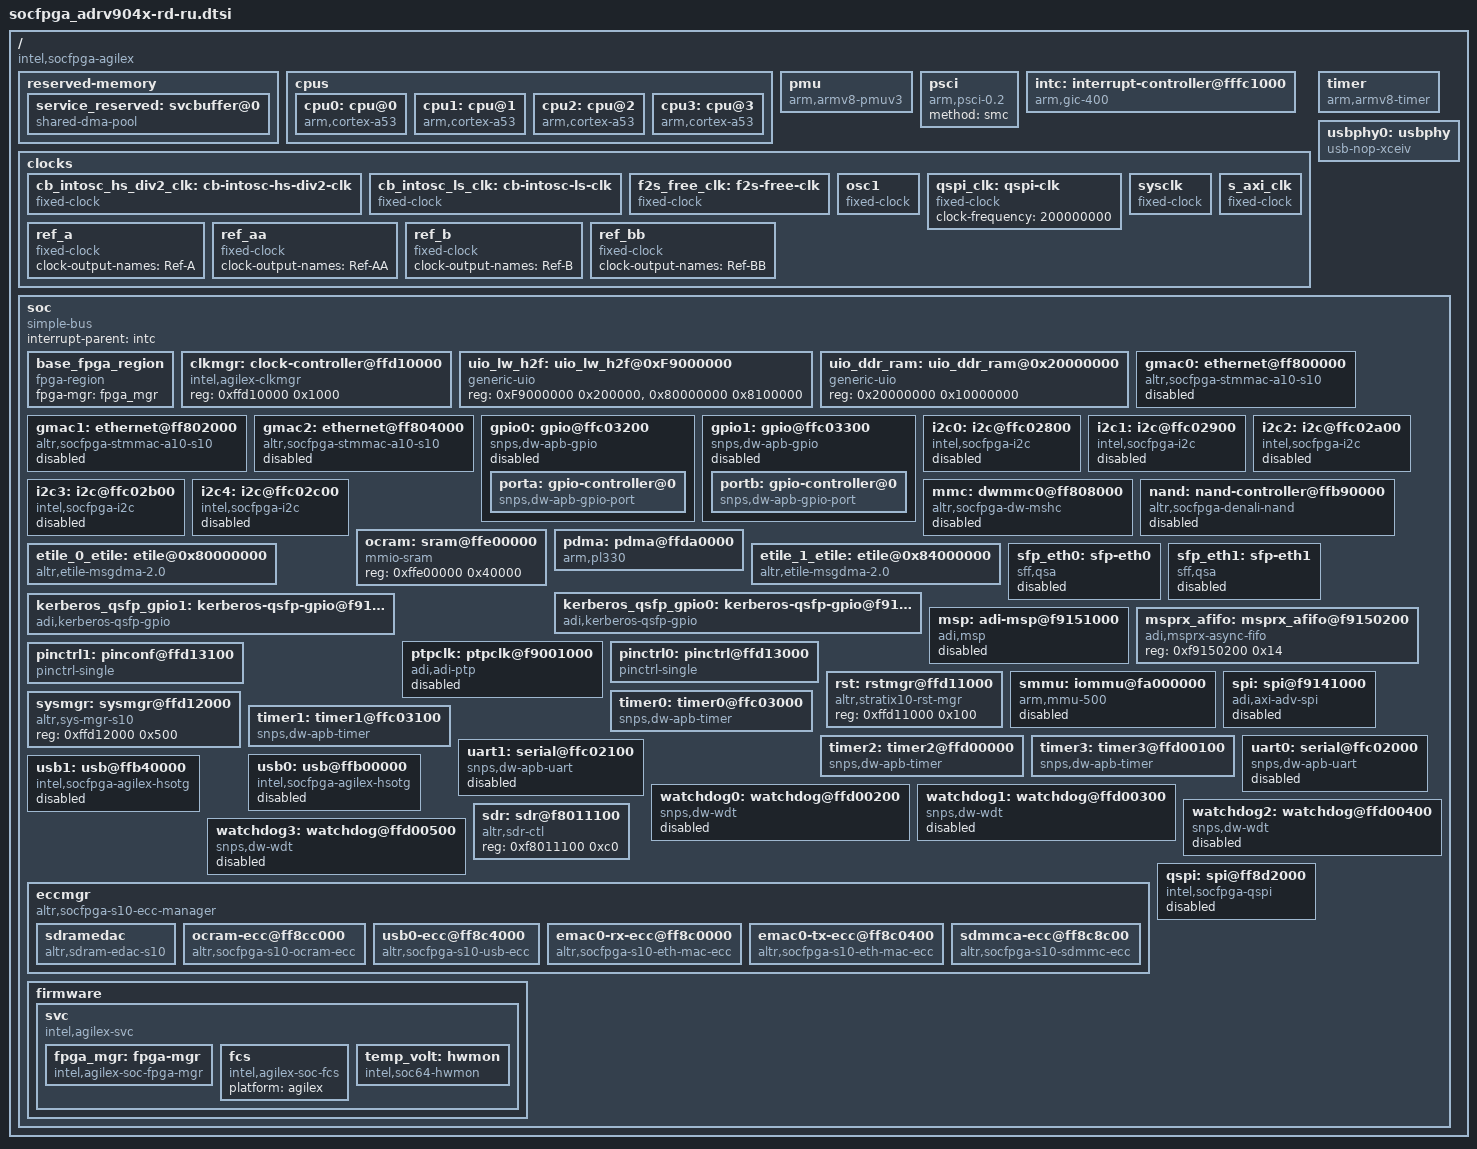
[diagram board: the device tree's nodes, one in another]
// SPDX-License-Identifier:     GPL-2.0
/*
 * Copyright (C) 2019, Intel Corporation
 */

/dts-v1/;
#include <dt-bindings/reset/altr,rst-mgr-s10.h>
#include <dt-bindings/gpio/gpio.h>
#include <dt-bindings/interrupt-controller/arm-gic.h>
#include <dt-bindings/clock/agilex-clock.h>
#include <dt-bindings/clock/ad9545.h>

/ {
	compatible = "intel,socfpga-agilex";
	#address-cells = <2>;
	#size-cells = <2>;

	reserved-memory {
		#address-cells = <2>;
		#size-cells = <2>;
		ranges;

		service_reserved: svcbuffer@0 {
			compatible = "shared-dma-pool";
			reg = <0x0 0x0 0x0 0x2000000>;
			alignment = <0x1000>;
			no-map;
		};
	};

	cpus {
		#address-cells = <1>;
		#size-cells = <0>;

		cpu0: cpu@0 {
			compatible = "arm,cortex-a53";
			device_type = "cpu";
			enable-method = "psci";
			reg = <0x0>;
		};

		cpu1: cpu@1 {
			compatible = "arm,cortex-a53";
			device_type = "cpu";
			enable-method = "psci";
			reg = <0x1>;
		};

		cpu2: cpu@2 {
			compatible = "arm,cortex-a53";
			device_type = "cpu";
			enable-method = "psci";
			reg = <0x2>;
		};

		cpu3: cpu@3 {
			compatible = "arm,cortex-a53";
			device_type = "cpu";
			enable-method = "psci";
			reg = <0x3>;
		};
	};

	pmu {
		compatible = "arm,armv8-pmuv3";
		interrupts = <GIC_SPI 170 IRQ_TYPE_LEVEL_HIGH>,
			     <GIC_SPI 171 IRQ_TYPE_LEVEL_HIGH>,
			     <GIC_SPI 172 IRQ_TYPE_LEVEL_HIGH>,
			     <GIC_SPI 173 IRQ_TYPE_LEVEL_HIGH>;
		interrupt-affinity = <&cpu0>,
				     <&cpu1>,
				     <&cpu2>,
				     <&cpu3>;
		interrupt-parent = <&intc>;
	};

	psci {
		compatible = "arm,psci-0.2";
		method = "smc";
	};

	intc: interrupt-controller@fffc1000 {
		compatible = "arm,gic-400", "arm,cortex-a15-gic";
		#interrupt-cells = <3>;
		interrupt-controller;
		reg = <0x0 0xfffc1000 0x0 0x1000>,
		      <0x0 0xfffc2000 0x0 0x2000>,
		      <0x0 0xfffc4000 0x0 0x2000>,
		      <0x0 0xfffc6000 0x0 0x2000>;
	};

	clocks {
		cb_intosc_hs_div2_clk: cb-intosc-hs-div2-clk {
			#clock-cells = <0>;
			compatible = "fixed-clock";
		};

		cb_intosc_ls_clk: cb-intosc-ls-clk {
			#clock-cells = <0>;
			compatible = "fixed-clock";
		};

		f2s_free_clk: f2s-free-clk {
			#clock-cells = <0>;
			compatible = "fixed-clock";
		};

		osc1: osc1 {
			#clock-cells = <0>;
			compatible = "fixed-clock";
		};

		qspi_clk: qspi-clk {
			#clock-cells = <0>;
			compatible = "fixed-clock";
			clock-frequency = <200000000>;
		};

		sysclk: sysclk {
			#clock-cells = <0>;
			compatible = "fixed-clock";
		};

		s_axi_clk: s_axi_clk {
			#clock-cells = <0>;
			compatible = "fixed-clock";
		};

		/* for AD9545 reference clocks */
		ref_a: ref_a {
			#clock-cells = <0>;
			compatible = "fixed-clock";
			clock-output-names = "Ref-A";
		};

		ref_aa: ref_aa {
			#clock-cells = <0>;
			compatible = "fixed-clock";
			clock-output-names = "Ref-AA";
		};

		ref_b: ref_b {
			#clock-cells = <0>;
			compatible = "fixed-clock";
			clock-output-names = "Ref-B";
		};

		ref_bb: ref_bb {
			#clock-cells = <0>;
			compatible = "fixed-clock";
			clock-output-names = "Ref-BB";
		};
	};

	timer {
		compatible = "arm,armv8-timer";
		interrupt-parent = <&intc>;
		interrupts = <GIC_PPI 13 (GIC_CPU_MASK_SIMPLE(4) | IRQ_TYPE_LEVEL_LOW)>,
			     <GIC_PPI 14 (GIC_CPU_MASK_SIMPLE(4) | IRQ_TYPE_LEVEL_LOW)>,
			     <GIC_PPI 11 (GIC_CPU_MASK_SIMPLE(4) | IRQ_TYPE_LEVEL_LOW)>,
			     <GIC_PPI 10 (GIC_CPU_MASK_SIMPLE(4) | IRQ_TYPE_LEVEL_LOW)>;
	};

	usbphy0: usbphy {
		#phy-cells = <0>;
		compatible = "usb-nop-xceiv";
		status = "okay";
	};

	soc {
		#address-cells = <1>;
		#size-cells = <1>;
		compatible = "simple-bus";
		device_type = "soc";
		interrupt-parent = <&intc>;
		ranges = <0 0 0 0xffffffff>;

		base_fpga_region {
			#address-cells = <0x2>;
			#size-cells = <0x2>;
			compatible = "fpga-region";
			fpga-mgr = <&fpga_mgr>;
		};

		clkmgr: clock-controller@ffd10000 {
			compatible = "intel,agilex-clkmgr";
			reg = <0xffd10000 0x1000>;
			#clock-cells = <1>;
		};

		uio_lw_h2f: uio_lw_h2f@0xF9000000 {
				compatible = "generic-uio";
				reg = <0xF9000000 0x200000>,
				      <0x80000000 0x8100000>;
				/*interrupts = <0 29 4>;*/
		};

		uio_ddr_ram: uio_ddr_ram@0x20000000 {
				compatible = "generic-uio";
				reg = <0x20000000 0x10000000>;
				/*interrupts = <0 29 4>;*/
		};

		gmac0: ethernet@ff800000 {
			compatible = "altr,socfpga-stmmac-a10-s10", "snps,dwmac-3.74a", "snps,dwmac";
			reg = <0xff800000 0x2000>;
			interrupts = <GIC_SPI 90 IRQ_TYPE_LEVEL_HIGH>;
			interrupt-names = "macirq";
			mac-address = [00 00 00 00 00 00];
			resets = <&rst EMAC0_RESET>, <&rst EMAC0_OCP_RESET>;
			reset-names = "stmmaceth", "stmmaceth-ocp";
			tx-fifo-depth = <16384>;
			rx-fifo-depth = <16384>;
			snps,multicast-filter-bins = <256>;
			iommus = <&smmu 1>;
			altr,sysmgr-syscon = <&sysmgr 0x44 0>;
			clocks = <&clkmgr AGILEX_EMAC0_CLK>, <&clkmgr AGILEX_EMAC_PTP_CLK>;
			clock-names = "stmmaceth", "ptp_ref";
			status = "disabled";
		};

		gmac1: ethernet@ff802000 {
			compatible = "altr,socfpga-stmmac-a10-s10", "snps,dwmac-3.74a", "snps,dwmac";
			reg = <0xff802000 0x2000>;
			interrupts = <GIC_SPI 91 IRQ_TYPE_LEVEL_HIGH>;
			interrupt-names = "macirq";
			mac-address = [00 00 00 00 00 00];
			resets = <&rst EMAC1_RESET>, <&rst EMAC1_OCP_RESET>;
			reset-names = "stmmaceth", "stmmaceth-ocp";
			tx-fifo-depth = <16384>;
			rx-fifo-depth = <16384>;
			snps,multicast-filter-bins = <256>;
			iommus = <&smmu 2>;
			altr,sysmgr-syscon = <&sysmgr 0x48 0>;
			clocks = <&clkmgr AGILEX_EMAC1_CLK>, <&clkmgr AGILEX_EMAC_PTP_CLK>;
			clock-names = "stmmaceth", "ptp_ref";
			status = "disabled";
		};

		gmac2: ethernet@ff804000 {
			compatible = "altr,socfpga-stmmac-a10-s10", "snps,dwmac-3.74a", "snps,dwmac";
			reg = <0xff804000 0x2000>;
			interrupts = <GIC_SPI 92 IRQ_TYPE_LEVEL_HIGH>;
			interrupt-names = "macirq";
			mac-address = [00 00 00 00 00 00];
			resets = <&rst EMAC2_RESET>, <&rst EMAC2_OCP_RESET>;
			reset-names = "stmmaceth", "stmmaceth-ocp";
			tx-fifo-depth = <16384>;
			rx-fifo-depth = <16384>;
			snps,multicast-filter-bins = <256>;
			iommus = <&smmu 3>;
			altr,sysmgr-syscon = <&sysmgr 0x4c 0>;
			clocks = <&clkmgr AGILEX_EMAC2_CLK>, <&clkmgr AGILEX_EMAC_PTP_CLK>;
			clock-names = "stmmaceth", "ptp_ref";
			status = "disabled";
		};

		gpio0: gpio@ffc03200 {
			#address-cells = <1>;
			#size-cells = <0>;
			compatible = "snps,dw-apb-gpio";
			reg = <0xffc03200 0x100>;
			resets = <&rst GPIO0_RESET>;
			status = "disabled";

			porta: gpio-controller@0 {
				compatible = "snps,dw-apb-gpio-port";
				gpio-controller;
				#gpio-cells = <2>;
				snps,nr-gpios = <24>;
				reg = <0>;
				interrupt-controller;
				#interrupt-cells = <2>;
				interrupts = <GIC_SPI 110 IRQ_TYPE_LEVEL_HIGH>;
			};
		};

		gpio1: gpio@ffc03300 {
			#address-cells = <1>;
			#size-cells = <0>;
			compatible = "snps,dw-apb-gpio";
			reg = <0xffc03300 0x100>;
			resets = <&rst GPIO1_RESET>;
			status = "disabled";

			portb: gpio-controller@0 {
				compatible = "snps,dw-apb-gpio-port";
				gpio-controller;
				#gpio-cells = <2>;
				snps,nr-gpios = <24>;
				reg = <0>;
				interrupt-controller;
				#interrupt-cells = <2>;
				interrupts = <GIC_SPI 111 IRQ_TYPE_LEVEL_HIGH>;
			};
		};

		i2c0: i2c@ffc02800 {
			#address-cells = <1>;
			#size-cells = <0>;
			compatible = "intel,socfpga-i2c", "snps,designware-i2c";
			reg = <0xffc02800 0x100>;
			interrupts = <GIC_SPI 103 IRQ_TYPE_LEVEL_HIGH>;
			resets = <&rst I2C0_RESET>;
			clocks = <&clkmgr AGILEX_L4_SP_CLK>;
			status = "disabled";
		};

		i2c1: i2c@ffc02900 {
			#address-cells = <1>;
			#size-cells = <0>;
			compatible = "intel,socfpga-i2c", "snps,designware-i2c";
			reg = <0xffc02900 0x100>;
			interrupts = <GIC_SPI 104 IRQ_TYPE_LEVEL_HIGH>;
			resets = <&rst I2C1_RESET>;
			clocks = <&clkmgr AGILEX_L4_SP_CLK>;
			status = "disabled";
		};

		i2c2: i2c@ffc02a00 {
			#address-cells = <1>;
			#size-cells = <0>;
			compatible = "intel,socfpga-i2c", "snps,designware-i2c";
			reg = <0xffc02a00 0x100>;
			interrupts = <GIC_SPI 105 IRQ_TYPE_LEVEL_HIGH>;
			resets = <&rst I2C2_RESET>;
			clocks = <&clkmgr AGILEX_L4_SP_CLK>;
			status = "disabled";
		};

		i2c3: i2c@ffc02b00 {
			#address-cells = <1>;
			#size-cells = <0>;
			compatible = "intel,socfpga-i2c", "snps,designware-i2c";
			reg = <0xffc02b00 0x100>;
			interrupts = <GIC_SPI 106 IRQ_TYPE_LEVEL_HIGH>;
			resets = <&rst I2C3_RESET>;
			clocks = <&clkmgr AGILEX_L4_SP_CLK>;
			status = "disabled";
		};

		i2c4: i2c@ffc02c00 {
			#address-cells = <1>;
			#size-cells = <0>;
			compatible = "intel,socfpga-i2c", "snps,designware-i2c";
			reg = <0xffc02c00 0x100>;
			interrupts = <GIC_SPI 107 IRQ_TYPE_LEVEL_HIGH>;
			resets = <&rst I2C4_RESET>;
			clocks = <&clkmgr AGILEX_L4_SP_CLK>;
			status = "disabled";
		};

		mmc: dwmmc0@ff808000 {
			#address-cells = <1>;
			#size-cells = <0>;
			compatible = "altr,socfpga-dw-mshc";
			reg = <0xff808000 0x1000>;
			interrupts = <GIC_SPI 96 IRQ_TYPE_LEVEL_HIGH>;
			fifo-depth = <0x400>;
			resets = <&rst SDMMC_RESET>;
			reset-names = "reset";
			clocks = <&clkmgr AGILEX_L4_MP_CLK>,
				 <&clkmgr AGILEX_SDMMC_CLK>;
			clock-names = "biu", "ciu";
			iommus = <&smmu 5>;
			status = "disabled";
		};

		nand: nand-controller@ffb90000 {
			#address-cells = <1>;
			#size-cells = <0>;
			compatible = "altr,socfpga-denali-nand";
			reg = <0xffb90000 0x10000>,
			      <0xffb80000 0x1000>;
			reg-names = "nand_data", "denali_reg";
			interrupts = <GIC_SPI 97 IRQ_TYPE_LEVEL_HIGH>;
			clocks = <&clkmgr AGILEX_NAND_CLK>,
				 <&clkmgr AGILEX_NAND_X_CLK>,
				 <&clkmgr AGILEX_NAND_ECC_CLK>;
			clock-names = "nand", "nand_x", "ecc";
			resets = <&rst NAND_RESET>, <&rst NAND_OCP_RESET>;
			status = "disabled";
		};

		ocram: sram@ffe00000 {
			compatible = "mmio-sram";
			reg = <0xffe00000 0x40000>;
		};

		pdma: pdma@ffda0000 {
			compatible = "arm,pl330", "arm,primecell";
			reg = <0xffda0000 0x1000>;
			interrupts = <GIC_SPI 81 IRQ_TYPE_LEVEL_HIGH>,
				     <GIC_SPI 82 IRQ_TYPE_LEVEL_HIGH>,
				     <GIC_SPI 83 IRQ_TYPE_LEVEL_HIGH>,
				     <GIC_SPI 84 IRQ_TYPE_LEVEL_HIGH>,
				     <GIC_SPI 85 IRQ_TYPE_LEVEL_HIGH>,
				     <GIC_SPI 86 IRQ_TYPE_LEVEL_HIGH>,
				     <GIC_SPI 87 IRQ_TYPE_LEVEL_HIGH>,
				     <GIC_SPI 88 IRQ_TYPE_LEVEL_HIGH>,
				     <GIC_SPI 89 IRQ_TYPE_LEVEL_HIGH>;
			#dma-cells = <1>;
			#dma-channels = <8>;
			#dma-requests = <32>;
			resets = <&rst DMA_RESET>, <&rst DMA_OCP_RESET>;
			reset-names = "dma", "dma-ocp";
			clocks = <&clkmgr AGILEX_L4_MAIN_CLK>;
			clock-names = "apb_pclk";
		};

		etile_0_etile: etile@0x80000000{
			compatible = "altr,etile-msgdma-2.0";
			reg-names = "eth_reconfig", "eth_ctrl";
			reg = <0x80000000 0x04000000>,
			      <0xf91401f0 0x4>;
			//dma-coherent;
			phy-mode = "25gbase-r";
			sfp = <&sfp_eth0>;

			/*
			clocks = <&ptp_ctrl_10G_clk>;
			clock-names = "tod_clk";
			interrupt-parent = <&intc>;
			interrupt-names = "tx_irq", "rx_irq";
			interrupts = <0 24 4>,
					<0 25 4>;
			rx-fifo-depth = <0x4000>;
			tx-fifo-depth = <0x1000>;
			rx-fifo-almost-full = <0x2000>;
			rx-fifo-almost-empty = <0x1000>;
			*/
			local-mac-address = [00 11 22 33 44 50];
			altr,tx-pma-delay-ns = <0xD>;
			altr,rx-pma-delay-ns = <0x8>;
			altr,tx-pma-delay-fns = <0x24D>;
			altr,rx-pma-delay-fns = <0x3E97>;
			altr,tx-external-phy-delay-ns = <0x0>;
			altr,rx-external-phy-delay-ns = <0x0>;
			fec-type = "kr-fec";
			fec-cw-pos-rx = <3>;
			//altr,has-ptp;
			status = "okay";
		};

		etile_1_etile: etile@0x84000000{
			compatible = "altr,etile-msgdma-2.0";
			reg-names = "eth_reconfig", "eth_ctrl";
			reg = <0x84000000 0x04000000>,
			      <0xf91401f4 0x4>;
			//dma-coherent;
			phy-mode = "25gbase-r";
			sfp = <&sfp_eth1>;

			/*
			clocks = <&ptp_ctrl_10G_clk>;
			clock-names = "tod_clk";
			interrupt-parent = <&intc>;
			interrupt-names = "tx_irq", "rx_irq";
			interrupts = <0 24 4>,
					<0 25 4>;
			rx-fifo-depth = <0x4000>;
			tx-fifo-depth = <0x1000>;
			rx-fifo-almost-full = <0x2000>;
			rx-fifo-almost-empty = <0x1000>;
			*/
			local-mac-address = [00 11 22 33 44 51];
			altr,tx-pma-delay-ns = <0xD>;
			altr,rx-pma-delay-ns = <0x8>;
			altr,tx-pma-delay-fns = <0x24D>;
			altr,rx-pma-delay-fns = <0x3E97>;
			altr,tx-external-phy-delay-ns = <0x0>;
			altr,rx-external-phy-delay-ns = <0x0>;
			fec-type = "kr-fec";
			fec-cw-pos-rx = <3>;
			altr,has-ptp;
			status = "okay";
		};

		sfp_eth0: sfp-eth0 {
			compatible = "sff,qsa";
			mod-def0-gpios = <&kerberos_qsfp_gpio0 4 GPIO_ACTIVE_LOW>;
			qsfpdd_modseln-gpio = <&kerberos_qsfp_gpio0 1 GPIO_ACTIVE_LOW>;
			maximum-power-milliwatt = <1000>;
			status = "disabled";
		};

		sfp_eth1: sfp-eth1 {
			compatible = "sff,qsa";
			mod-def0-gpios = <&kerberos_qsfp_gpio1 4 GPIO_ACTIVE_LOW>;
			qsfpdd_modseln-gpio = <&kerberos_qsfp_gpio1 1 GPIO_ACTIVE_LOW>;
			maximum-power-milliwatt = <1000>;
			status = "disabled";
		};

		kerberos_qsfp_gpio0: kerberos-qsfp-gpio@f9140154{
			compatible = "adi,kerberos-qsfp-gpio";
			reg = <0xf9140154 0x14>;
			#gpio-cells = <2>;
			gpio-controller;
			status = "okay";
		};

		kerberos_qsfp_gpio1: kerberos-qsfp-gpio@f9140168{
			compatible = "adi,kerberos-qsfp-gpio";
			reg = <0xf9140168 0x14>;
			#gpio-cells = <2>;
			gpio-controller;
			status = "okay";
		};

		msp: adi-msp@f9151000 {
			#address-cells = <1>;
			#size-cells = <1>;
			compatible = "adi,msp";
			reg = <0x8800b800 0x2800>, <0x88004300 0x1300>,
			      <0xf9150200 0x14>,
			      <0xf91401d0 0x10>,
			      <0xf9150000 0x50>, <0xf9151000 0x118>,
			      <0xf9150100 0x4>,
			      <0xf9152000 0x118>, <0xf9150300 0x50>,
			      <0xf9150500 0x50>;
			reg-names = "oif_tx", "oif_rx",
				    "async_fifo_rx",
				    "axi_palau_gpio_msp_ctrl",
				    "rx_dma", "rx",
				    "dde_tester",
				    "tx", "tx_dma",
				    "status_dma";
			/* 53 + 32 = 85 --> interrupt_2_sic */
			/* 55 + 32 = 87 --> dde_error_intr */
			interrupts = <0 53 4>, <0 55 4>,
				     <0 60 4>, <0 58 4>,
				     <0 63 4>, <0 64 4>;
			interrupt-names = "rx_dmadone_irq", "rx_dde_error_irq",
					  "tx_dmadone_irq", "tx_dde_error_irq",
					  "status_dmadone_irq",
					  "status_dde_error_irq";
			local-mac-address = [00 11 22 33 44 52];
			adi,etile = <&etile_1_etile>;
			status = "disabled";
		};

		msprx_afifo: msprx_afifo@f9150200 {
			#address-cells = <1>;
			#size-cells = <1>;
			compatible = "adi,msprx-async-fifo";
			reg = <0xf9150200 0x14>;
			reg-names = "msprx_afifo";
		};

		ptpclk: ptpclk@f9001000 {
			compatible = "adi,adi-ptp";
			reg = <0xf9001000 0xff>, <0xf9140144 0x4>;
			reg-names = "tod", "axi_palau_gpio_pps_ctrl";
			adi,max-adj = <131072>;
			adi,trigger-mode = <1>;
			adi,trigger-delay-tick = <491520>;
			adi,ppsx-delay-offset-ns = <0>;
			adi,ppsx-pulse-width-ns = <256>;
			status = "disabled";
		};

		pinctrl0: pinctrl@ffd13000 {
			compatible = "pinctrl-single";
			#pinctrl-cells = <1>;
			reg = <0xffd13000 0xa0>;
			pinctrl-single,register-width = <32>;
			pinctrl-single,function-mask = <0x0000000f>;
		};

		pinctrl1: pinconf@ffd13100 {
			compatible = "pinctrl-single";
			#pinctrl-cells = <1>;
			reg = <0xffd13100 0x20>;
			pinctrl-single,register-width = <32>;
		};

		rst: rstmgr@ffd11000 {
			#reset-cells = <1>;
			compatible = "altr,stratix10-rst-mgr";
			reg = <0xffd11000 0x100>;
		};

		smmu: iommu@fa000000 {
			compatible = "arm,mmu-500", "arm,smmu-v2";
			reg = <0xfa000000 0x40000>;
			#global-interrupts = <2>;
			#iommu-cells = <1>;
			interrupt-parent = <&intc>;
			/* Global Secure Fault */
			interrupts = <GIC_SPI 128 IRQ_TYPE_LEVEL_HIGH>,
				/* Global Non-secure Fault */
				<GIC_SPI 129 IRQ_TYPE_LEVEL_HIGH>,
				/* Non-secure Context Interrupts (32) */
				<GIC_SPI 138 IRQ_TYPE_LEVEL_HIGH>,
				<GIC_SPI 139 IRQ_TYPE_LEVEL_HIGH>,
				<GIC_SPI 140 IRQ_TYPE_LEVEL_HIGH>,
				<GIC_SPI 141 IRQ_TYPE_LEVEL_HIGH>,
				<GIC_SPI 142 IRQ_TYPE_LEVEL_HIGH>,
				<GIC_SPI 143 IRQ_TYPE_LEVEL_HIGH>,
				<GIC_SPI 144 IRQ_TYPE_LEVEL_HIGH>,
				<GIC_SPI 145 IRQ_TYPE_LEVEL_HIGH>,
				<GIC_SPI 146 IRQ_TYPE_LEVEL_HIGH>,
				<GIC_SPI 147 IRQ_TYPE_LEVEL_HIGH>,
				<GIC_SPI 148 IRQ_TYPE_LEVEL_HIGH>,
				<GIC_SPI 149 IRQ_TYPE_LEVEL_HIGH>,
				<GIC_SPI 150 IRQ_TYPE_LEVEL_HIGH>,
				<GIC_SPI 151 IRQ_TYPE_LEVEL_HIGH>,
				<GIC_SPI 152 IRQ_TYPE_LEVEL_HIGH>,
				<GIC_SPI 153 IRQ_TYPE_LEVEL_HIGH>,
				<GIC_SPI 154 IRQ_TYPE_LEVEL_HIGH>,
				<GIC_SPI 155 IRQ_TYPE_LEVEL_HIGH>,
				<GIC_SPI 156 IRQ_TYPE_LEVEL_HIGH>,
				<GIC_SPI 157 IRQ_TYPE_LEVEL_HIGH>,
				<GIC_SPI 158 IRQ_TYPE_LEVEL_HIGH>,
				<GIC_SPI 159 IRQ_TYPE_LEVEL_HIGH>,
				<GIC_SPI 160 IRQ_TYPE_LEVEL_HIGH>,
				<GIC_SPI 161 IRQ_TYPE_LEVEL_HIGH>,
				<GIC_SPI 162 IRQ_TYPE_LEVEL_HIGH>,
				<GIC_SPI 163 IRQ_TYPE_LEVEL_HIGH>,
				<GIC_SPI 164 IRQ_TYPE_LEVEL_HIGH>,
				<GIC_SPI 165 IRQ_TYPE_LEVEL_HIGH>,
				<GIC_SPI 166 IRQ_TYPE_LEVEL_HIGH>,
				<GIC_SPI 167 IRQ_TYPE_LEVEL_HIGH>,
				<GIC_SPI 168 IRQ_TYPE_LEVEL_HIGH>,
				<GIC_SPI 169 IRQ_TYPE_LEVEL_HIGH>;
			stream-match-mask = <0x7ff0>;
			clocks = <&clkmgr AGILEX_MPU_CCU_CLK>,
				 <&clkmgr AGILEX_L3_MAIN_FREE_CLK>,
				 <&clkmgr AGILEX_L4_MAIN_CLK>;
			status = "disabled";
		};

		spi: spi@f9141000{
			compatible = "adi,axi-adv-spi";
			reg = <0xf9141000 0x1000>;
			#address-cells = <1>;
			#size-cells = <0>;
			clocks = <&s_axi_clk>;
			status = "disabled";
		};

		sysmgr: sysmgr@ffd12000 {
			compatible = "altr,sys-mgr-s10","altr,sys-mgr";
			reg = <0xffd12000 0x500>;
		};

		timer0: timer0@ffc03000 {
			compatible = "snps,dw-apb-timer";
			interrupts = <GIC_SPI 113 IRQ_TYPE_LEVEL_HIGH>;
			reg = <0xffc03000 0x100>;
			clocks = <&clkmgr AGILEX_L4_SP_CLK>;
			clock-names = "timer";
		};

		timer1: timer1@ffc03100 {
			compatible = "snps,dw-apb-timer";
			interrupts = <GIC_SPI 114 IRQ_TYPE_LEVEL_HIGH>;
			reg = <0xffc03100 0x100>;
			clocks = <&clkmgr AGILEX_L4_SP_CLK>;
			clock-names = "timer";
		};

		timer2: timer2@ffd00000 {
			compatible = "snps,dw-apb-timer";
			interrupts = <GIC_SPI 115 IRQ_TYPE_LEVEL_HIGH>;
			reg = <0xffd00000 0x100>;
			clocks = <&clkmgr AGILEX_L4_SP_CLK>;
			clock-names = "timer";
		};

		timer3: timer3@ffd00100 {
			compatible = "snps,dw-apb-timer";
			interrupts = <GIC_SPI 116 IRQ_TYPE_LEVEL_HIGH>;
			reg = <0xffd00100 0x100>;
			clocks = <&clkmgr AGILEX_L4_SP_CLK>;
			clock-names = "timer";
		};

		uart0: serial@ffc02000 {
			compatible = "snps,dw-apb-uart";
			reg = <0xffc02000 0x100>;
			interrupts = <GIC_SPI 108 IRQ_TYPE_LEVEL_HIGH>;
			reg-shift = <2>;
			reg-io-width = <4>;
			resets = <&rst UART0_RESET>;
			clocks = <&clkmgr AGILEX_L4_SP_CLK>;
			status = "disabled";
		};

		uart1: serial@ffc02100 {
			compatible = "snps,dw-apb-uart";
			reg = <0xffc02100 0x100>;
			interrupts = <GIC_SPI 109 IRQ_TYPE_LEVEL_HIGH>;
			reg-shift = <2>;
			reg-io-width = <4>;
			resets = <&rst UART1_RESET>;
			clocks = <&clkmgr AGILEX_L4_SP_CLK>;
			status = "disabled";
		};

		usb0: usb@ffb00000 {
			compatible = "intel,socfpga-agilex-hsotg", "snps,dwc2";
			reg = <0xffb00000 0x40000>;
			interrupts = <GIC_SPI 93 IRQ_TYPE_LEVEL_HIGH>;
			phys = <&usbphy0>;
			phy-names = "usb2-phy";
			resets = <&rst USB0_RESET>, <&rst USB0_OCP_RESET>;
			reset-names = "dwc2", "dwc2-ecc";
			clocks = <&clkmgr AGILEX_USB_CLK>;
			iommus = <&smmu 6>;
			status = "disabled";
		};

		usb1: usb@ffb40000 {
			compatible = "intel,socfpga-agilex-hsotg", "snps,dwc2";
			reg = <0xffb40000 0x40000>;
			interrupts = <GIC_SPI 94 IRQ_TYPE_LEVEL_HIGH>;
			phys = <&usbphy0>;
			phy-names = "usb2-phy";
			resets = <&rst USB1_RESET>, <&rst USB1_OCP_RESET>;
			reset-names = "dwc2", "dwc2-ecc";
			iommus = <&smmu 7>;
			clocks = <&clkmgr AGILEX_USB_CLK>;
			status = "disabled";
		};

		watchdog0: watchdog@ffd00200 {
			compatible = "snps,dw-wdt";
			reg = <0xffd00200 0x100>;
			interrupts = <GIC_SPI 117 IRQ_TYPE_LEVEL_HIGH>;
			resets = <&rst WATCHDOG0_RESET>;
			clocks = <&clkmgr AGILEX_L4_SYS_FREE_CLK>;
			status = "disabled";
		};

		watchdog1: watchdog@ffd00300 {
			compatible = "snps,dw-wdt";
			reg = <0xffd00300 0x100>;
			interrupts = <GIC_SPI 118 IRQ_TYPE_LEVEL_HIGH>;
			resets = <&rst WATCHDOG1_RESET>;
			clocks = <&clkmgr AGILEX_L4_SYS_FREE_CLK>;
			status = "disabled";
		};

		watchdog2: watchdog@ffd00400 {
			compatible = "snps,dw-wdt";
			reg = <0xffd00400 0x100>;
			interrupts = <GIC_SPI 125 IRQ_TYPE_LEVEL_HIGH>;
			resets = <&rst WATCHDOG2_RESET>;
			clocks = <&clkmgr AGILEX_L4_SYS_FREE_CLK>;
			status = "disabled";
		};

		watchdog3: watchdog@ffd00500 {
			compatible = "snps,dw-wdt";
			reg = <0xffd00500 0x100>;
			interrupts = <GIC_SPI 126 IRQ_TYPE_LEVEL_HIGH>;
			resets = <&rst WATCHDOG3_RESET>;
			clocks = <&clkmgr AGILEX_L4_SYS_FREE_CLK>;
			status = "disabled";
		};

		sdr: sdr@f8011100 {
			compatible = "altr,sdr-ctl", "syscon";
			reg = <0xf8011100 0xc0>;
		};

		eccmgr {
			compatible = "altr,socfpga-s10-ecc-manager",
				     "altr,socfpga-a10-ecc-manager";
			altr,sysmgr-syscon = <&sysmgr>;
			#address-cells = <1>;
			#size-cells = <1>;
			interrupts = <GIC_SPI 15 IRQ_TYPE_LEVEL_HIGH>;
			interrupt-controller;
			#interrupt-cells = <2>;
			ranges;

			sdramedac {
				compatible = "altr,sdram-edac-s10";
				altr,sdr-syscon = <&sdr>;
				interrupts = <16 4>;
			};

			ocram-ecc@ff8cc000 {
				compatible = "altr,socfpga-s10-ocram-ecc",
					     "altr,socfpga-a10-ocram-ecc";
				reg = <0xff8cc000 0x100>;
				altr,ecc-parent = <&ocram>;
				interrupts = <1 4>;
			};

			usb0-ecc@ff8c4000 {
				compatible = "altr,socfpga-s10-usb-ecc",
					     "altr,socfpga-usb-ecc";
				reg = <0xff8c4000 0x100>;
				altr,ecc-parent = <&usb0>;
				interrupts = <2 4>;
			};

			emac0-rx-ecc@ff8c0000 {
				compatible = "altr,socfpga-s10-eth-mac-ecc",
					     "altr,socfpga-eth-mac-ecc";
				reg = <0xff8c0000 0x100>;
				altr,ecc-parent = <&gmac0>;
				interrupts = <4 4>;
			};

			emac0-tx-ecc@ff8c0400 {
				compatible = "altr,socfpga-s10-eth-mac-ecc",
					     "altr,socfpga-eth-mac-ecc";
				reg = <0xff8c0400 0x100>;
				altr,ecc-parent = <&gmac0>;
				interrupts = <5 4>;
			};

			sdmmca-ecc@ff8c8c00 {
				compatible = "altr,socfpga-s10-sdmmc-ecc",
					     "altr,socfpga-sdmmc-ecc";
				reg = <0xff8c8c00 0x100>;
				altr,ecc-parent = <&mmc>;
				interrupts = <14 4>,
					     <15 4>;
			};
		};

		qspi: spi@ff8d2000 {
			compatible = "intel,socfpga-qspi", "cdns,qspi-nor";
			#address-cells = <1>;
			#size-cells = <0>;
			reg = <0xff8d2000 0x100>,
			      <0xff900000 0x100000>;
			interrupts = <GIC_SPI 3 IRQ_TYPE_LEVEL_HIGH>;
			cdns,fifo-depth = <128>;
			cdns,fifo-width = <4>;
			cdns,trigger-address = <0x00000000>;
			clocks = <&qspi_clk>;

			status = "disabled";
		};

		firmware {
			svc {
				compatible = "intel,agilex-svc";
				method = "smc";
				memory-region = <&service_reserved>;

				fpga_mgr: fpga-mgr {
					compatible = "intel,agilex-soc-fpga-mgr";
				};

				fcs: fcs {
					compatible = "intel,agilex-soc-fcs";
					platform = "agilex";
				};

				temp_volt: hwmon {
					compatible = "intel,soc64-hwmon";
				};
			};
		};
	};
};
